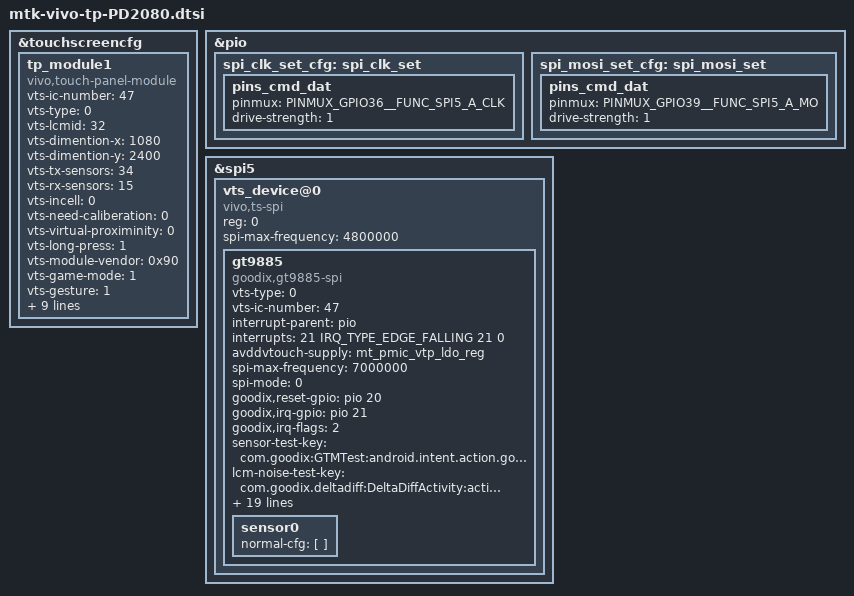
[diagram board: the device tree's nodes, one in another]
/*********************touch screen config *************************/
&touchscreencfg { /* vivo ts configure */
		
 tp_module1 {
		compatible = "vivo,touch-panel-module";
		vts-ic-number=<47>;
		vts-type=<0>;
		vts-lcmid=<32>;//0x20
		vts-dimention-x=<1080>;
		vts-dimention-y=<2400>;
		vts-tx-sensors=<34>;
		vts-rx-sensors=<15>;
		vts-incell=<0>;
 		vts-need-caliberation=<0>;
 		vts-virtual-proximinity=<0>;
 		vts-long-press=<1>;
		vts-module-vendor=<0x90>;
		vts-game-mode=<1>;
		vts-gesture=<1>;
		vts-game-high_rate=<1>;//0:keep prev   1: high_rate  2:normal_rate 
		vts-game-idle-time=<10>;//0: keep prev  FF:ic default time , 0~ff: enter idle time    
		vts-fp-feedback=<1>;
		vts-input-method=<1>;
		vts-bus-state-set=<1>;
		vts-finger-mode=<1>;
		vts-screen-clock=<1>;
		vts-sclock-hilight=<1>;
		vts-report-timestamp=<1>;
	};
};

&pio {
	spi_clk_set_cfg:spi_clk_set {
		pins_cmd_dat {
			pinmux = <PINMUX_GPIO36__FUNC_SPI5_A_CLK>;
			drive-strength = <1>; //0:2mA 1:4mA 2:6mA 3:8mA 4:10mA 5:12mA 6:14mA 7:16mA
		};
	};

	spi_mosi_set_cfg:spi_mosi_set {
		pins_cmd_dat {
			pinmux = <PINMUX_GPIO39__FUNC_SPI5_A_MO>;
			drive-strength = <1>; //0:2mA 1:4mA 2:6mA 3:8mA 4:10mA 5:12mA 6:14mA 7:16mA
		};
	};
};

&spi5 {
	#address-cells = <1>;
	#size-cells = <0>;	
	
	vts_device@0 {
		compatible = "vivo,ts-spi";
		status = "okay";
		reg=<0>;
		spi-max-frequency = <4800000>;
		gt9885 {
			compatible = "goodix,gt9885-spi";
			status = "ok";
			vts-type=<0>;
			vts-ic-number=<47>;
			interrupt-parent = <&pio>;
			interrupts = <21 IRQ_TYPE_EDGE_FALLING 21 0>;
			avddvtouch-supply = <&mt_pmic_vtp_ldo_reg>;	/*3V PMIC*/
			//vtouch-supply = <&pm8150_l16>;//1V8 接INT 需要上电
			spi-max-frequency = <7000000>;	
			spi-mode = <0>;	
			goodix,reset-gpio = <&pio 20 0x00>;
			goodix,irq-gpio = <&pio 21 0x00>;
			goodix,irq-flags = <2>; /* 1:trigger rising, 2:trigger falling;*/
			//pinctrl-names ="default";
			//pinctrl-0 = <&int_suspend_2001>;
			sensor-test-key= "com.goodix:GTMTest:android.intent.action.goodix:0:goodixTestResult";
			lcm-noise-test-key="com.goodix.deltadiff:DeltaDiffActivity:action.null:null:null";
			rawdata-test-key="com.goodix.deltadiff:DataShowActivity:null:null:null";
			rf-noise-test-key="com.goodix.deltadiff:BspTestActivity:com.goodix.deltadiff.action.Receiver:0:GOODIX_DELTA";
			goodix,panel-max-id = <10>;
			goodix,panel-max-x = <1080>;
			goodix,panel-max-y = <2400>;
			goodix,panel-max-w = <512>;
			goodix,panel-max-p = <512>;
			goodix,panel-key-map = <158 172 217>; /*KEY_BACK, KEY_HOMEPAGE, KEY_SEARCH*/
			goodix,power-on-delay-us = <30000>; /*300ms*/
			goodix,power-off-delay-us = <5000>;
			goodix,i2c-read-max-size = <1>;/*i2c read max byte one time, when spi mode ,this value should be zero or one */

			pinctrl-names = "spi_clk_active", "spi_mosi_active";
			pinctrl-0 = <&spi_clk_set_cfg>;
			pinctrl-1 = <&spi_mosi_set_cfg>;

			/*goodix,swap-axis;*/
			goodix,x2x;
			goodix,y2y;
			goodix,pen-enable;
			goodix,key-of-pen = <331 332>;/*BTN_STYLUS, BTN_STYLUS2*/
			sensor0 {
				normal-cfg = [
				];
			};
			
		};
		
};
};
	
